# S6E1A1 register map
File version: 1.2
CPU: 
Registers are 32-bit, read-write, reset 0x0 unless marked. A register's access mark holds for its fields unless they carry their own. Offsets are from the block's base; [hi:lo] are bit positions; {n}, {i} and the like mark numbered series.

## MFT_PPG — PPG Configuration Registers
Base 0x40024000
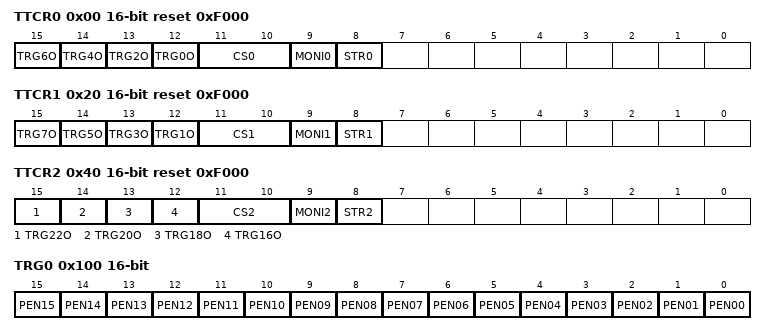
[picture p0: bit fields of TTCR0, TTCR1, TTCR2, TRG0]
0x00 TTCR0 16-bit reset 0xF000 — PPG Start Trigger Control Register 0
  [15] TRG6O wo — PPG6 trigger stop bit
  [14] TRG4O wo — PPG4 trigger stop bit
  [13] TRG2O wo — PPG2 trigger stop bit
  [12] TRG0O wo — PPG0 trigger stop bit
  [11:10] CS0 — 8-bit UP counter clock select bits for comparison
  [9] MONI0 ro — 8-bit UP counter operation state monitor bit for comparison
  [8] STR0 wo — 8-bit UP counter operation enable bit for comparison
0x09 COMP0 8-bit — PPG Compare Register 0
0x0C COMP2 8-bit — PPG Compare Register 2
0x11 COMP4 reset not defined — PPG Compare Register 4
0x14 COMP6 reset not defined — PPG Compare Register 6
0x20 TTCR1 16-bit reset 0xF000 — PPG Start Trigger Control Register 1
  [15] TRG7O wo — PPG7 trigger stop bit
  [14] TRG5O wo — PPG5 trigger stop bit
  [13] TRG3O wo — PPG3 trigger stop bit
  [12] TRG1O wo — PPG1 trigger stop bit
  [11:10] CS1 — 8-bit UP counter clock select bits for comparison
  [9] MONI1 ro — 8-bit UP counter operation state monitor bit for comparison
  [8] STR1 wo — 8-bit UP counter operation enable bit for comparison
0x29 COMP1 reset not defined — PPG Compare Register 1
0x2C COMP3 reset not defined — PPG Compare Register 3
0x31 COMP5 reset not defined — PPG Compare Register 5
0x34 COMP7 reset not defined — PPG Compare Register 7
0x40 TTCR2 16-bit reset 0xF000 — PPG Start Trigger Control Register 2
  [15] TRG22O wo — PPG22 trigger stop bit
  [14] TRG20O wo — PPG20 trigger stop bit
  [13] TRG18O wo — PPG18 trigger stop bit
  [12] TRG16O wo — PPG16 trigger stop bit
  [11:10] CS2 — 8-bit UP counter clock select bits for comparison
  [9] MONI2 ro — 8-bit UP counter operation state monitor bit for comparison
  [8] STR2 wo — 8-bit UP counter operation enable bit for comparison
0x49 COMP8 reset not defined — PPG Compare Register 8
0x4C COMP10 reset not defined — PPG Compare Register 10
0x51 COMP12 reset not defined — PPG Compare Register 12
0x54 COMP14 reset not defined — PPG Compare Register 14
0x100 TRG0 16-bit — PPG Start Register 0
  [n] PEN{n:02} (n=0..15) — PPG{n} Start Trigger bit
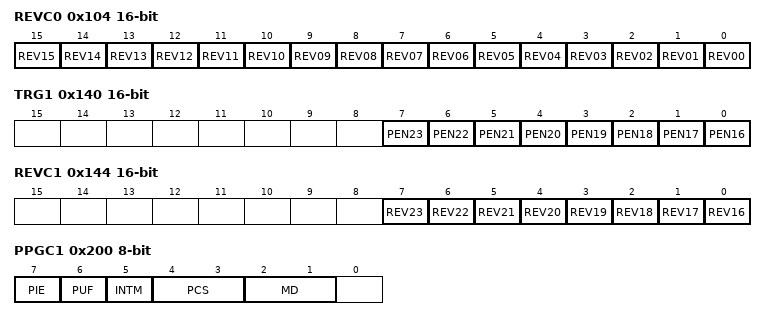
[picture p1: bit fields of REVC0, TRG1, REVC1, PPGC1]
0x104 REVC0 16-bit — Output Reverse Register 0
  [n] REV{n:02} (n=0..15) — PPG{n} Output Reverse Enable bit
0x140 TRG1 16-bit — PPG Start Register 1
  [n-16] PEN{n} (n=16..23) — PPG{n} Start Trigger bit
0x144 REVC1 16-bit — Output Reverse Register 1
  [n-16] REV{n} (n=16..23) — PPG{n} Output Reverse Enable bit
0x200 PPGC1 8-bit (reset mask 0xF8) — PPG Operation Mode Control Register 1
  [7] PIE — PPG Interrupt Enable bit
  [6] PUF — PPG Counter Underflow bit
  [5] INTM — Interrupt Mode Select bit
  [4:3] PCS — PPG DOWN Counter Operation Clock Select bits
  [2:1] MD — PPG Operation Mode Set bits
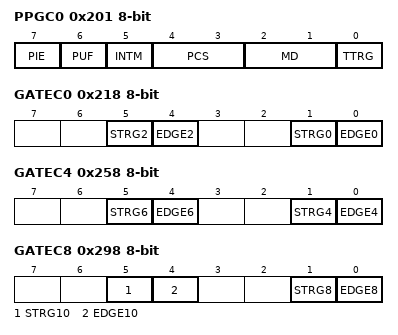
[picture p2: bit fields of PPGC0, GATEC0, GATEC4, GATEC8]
0x201 PPGC0 8-bit — PPG Operation Mode Control Register 0
  [7] PIE — PPG Interrupt Enable bit
  [6] PUF — PPG Counter Underflow bit
  [5] INTM — Interrupt Mode Select bit
  [4:3] PCS — PPG DOWN Counter Operation Clock Select bits
  [2:1] MD — PPG Operation Mode Set bits
  [0] TTRG — PPG start trigger select bit
0x204 PPGC3 reset not defined — PPG Operation Mode Control Register 3
0x205 PPGC2 reset not defined — PPG Operation Mode Control Register 2
0x208 PRLL0 8-bit — PPG0 Reload Registers Low
  [7:0] PRLL — Reload Registers Low
0x209 PRLH0 8-bit — PPG0 Reload Registers High
  [7:0] PRLH — Reload Registers High
{0x208+4i} PRLL{i} reset not defined (i=1..3) — PPG{i} Reload Registers Low
{0x209+4i} PRLH{i} reset not defined (i=1..3) — PPG{i} Reload Registers High
0x218 GATEC0 8-bit — PPG Gate Function Control Register 0
  [5] STRG2 — Select trigger bit for PPG2
  [4] EDGE2 — Start Effective Level Select bit for PPG2
  [1] STRG0 — Select trigger bit for PPG0
  [0] EDGE0 — Start Effective Level Select bit for PPG0
0x240 PPGC5 reset not defined — PPG Operation Mode Control Register 5
0x241 PPGC4 reset not defined — PPG Operation Mode Control Register 4
0x244 PPGC7 reset not defined — PPG Operation Mode Control Register 7
0x245 PPGC6 reset not defined — PPG Operation Mode Control Register 6
{0x238+4i} PRLL{i} reset not defined (i=4..7) — PPG{i} Reload Registers Low
{0x239+4i} PRLH{i} reset not defined (i=4..7) — PPG{i} Reload Registers High
0x258 GATEC4 8-bit — PPG Gate Function Control Register 4
  [5] STRG6 — Select trigger bit for PPG6
  [4] EDGE6 — Start Effective Level Select bit for PPG6
  [1] STRG4 — Select trigger bit for PPG4
  [0] EDGE4 — Start Effective Level Select bit for PPG4
0x280 PPGC9 reset not defined — PPG Operation Mode Control Register 9
0x281 PPGC8 reset not defined — PPG Operation Mode Control Register 8
0x284 PPGC11 reset not defined — PPG Operation Mode Control Register 11
0x285 PPGC10 reset not defined — PPG Operation Mode Control Register 10
{0x268+4i} PRLL{i} reset not defined (i=8..11) — PPG{i} Reload Registers Low
{0x269+4i} PRLH{i} reset not defined (i=8..11) — PPG{i} Reload Registers High
0x298 GATEC8 8-bit — PPG Gate Function Control Register 8
  [5] STRG10 — Select trigger bit for PPG10
  [4] EDGE10 — Start Effective Level Select bit for PPG10
  [1] STRG8 — Select trigger bit for PPG8
  [0] EDGE8 — Start Effective Level Select bit for PPG8
0x2C0 PPGC13 reset not defined — PPG Operation Mode Control Register 13
0x2C1 PPGC12 reset not defined — PPG Operation Mode Control Register 12
0x2C4 PPGC15 reset not defined — PPG Operation Mode Control Register 15
0x2C5 PPGC14 reset not defined — PPG Operation Mode Control Register 14
{0x298+4i} PRLL{i} reset not defined (i=12..15) — PPG{i} Reload Registers Low
{0x299+4i} PRLH{i} reset not defined (i=12..15) — PPG{i} Reload Registers High
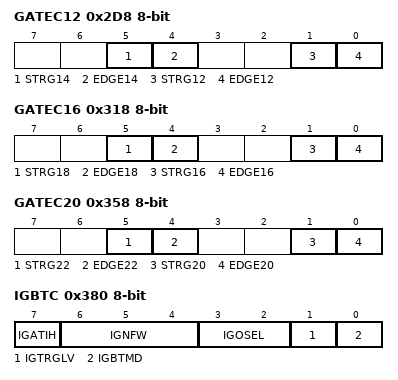
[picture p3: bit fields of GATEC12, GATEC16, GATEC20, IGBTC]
0x2D8 GATEC12 8-bit — PPG Gate Function Control Register 12
  [5] STRG14 — Select trigger bit for PPG14
  [4] EDGE14 — Start Effective Level Select bit for PPG14
  [1] STRG12 — Select trigger bit for PPG12
  [0] EDGE12 — Start Effective Level Select bit for PPG12
0x300 PPGC17 reset not defined — PPG Operation Mode Control Register 17
0x301 PPGC16 reset not defined — PPG Operation Mode Control Register 16
0x304 PPGC19 reset not defined — PPG Operation Mode Control Register 19
0x305 PPGC18 reset not defined — PPG Operation Mode Control Register 18
{0x2C8+4i} PRLL{i} reset not defined (i=16..19) — PPG{i} Reload Registers Low
{0x2C9+4i} PRLH{i} reset not defined (i=16..19) — PPG{i} Reload Registers High
0x318 GATEC16 8-bit — PPG Gate Function Control Register 16
  [5] STRG18 — Select trigger bit for PPG18
  [4] EDGE18 — Start Effective Level Select bit for PPG18
  [1] STRG16 — Select trigger bit for PPG16
  [0] EDGE16 — Start Effective Level Select bit for PPG16
0x340 PPGC21 reset not defined — PPG Operation Mode Control Register 21
0x341 PPGC20 reset not defined — PPG Operation Mode Control Register 20
0x344 PPGC23 reset not defined — PPG Operation Mode Control Register 23
0x345 PPGC22 reset not defined — PPG Operation Mode Control Register 22
{0x2F8+4i} PRLL{i} reset not defined (i=20..23) — PPG{i} Reload Registers Low
{0x2F9+4i} PRLH{i} reset not defined (i=20..23) — PPG{i} Reload Registers High
0x358 GATEC20 8-bit — PPG Gate Function Control Register 20
  [5] STRG22 — Select trigger bit for PPG22
  [4] EDGE22 — Start Effective Level Select bit for PPG22
  [1] STRG20 — Select trigger bit for PPG20
  [0] EDGE20 — Start Effective Level Select bit for PPG20
0x380 IGBTC 8-bit — IGBT Mode Control Register
  [7] IGATIH — Stop prohibition mode selection in output active bit
  [6:4] IGNFW — Noise filter width selection bit
  [3:2] IGOSEL — Output level selection bit
  [1] IGTRGLV — Trigger input level selection bit
  [0] IGBTMD — IGBT mode selection bit
